# AVR32SD28 device description
Architecture: AVR8X; Family: AVR
Registers are 8-bit, read-write, reset 0x0 unless marked. A register's access mark holds for its fields unless they carry their own. Offsets are from the block's base; [hi:lo] are bit positions; {n}, {i} and the like mark numbered series; 'fields as' and 'values as' point back to an identical list.

## FUSE — Fuses
Instances: FUSE 0x1050
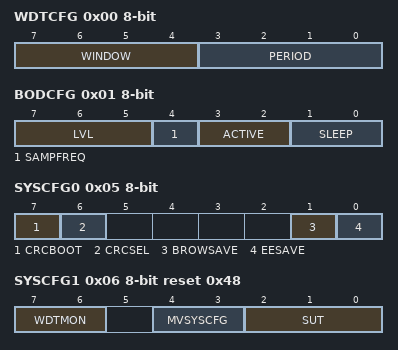
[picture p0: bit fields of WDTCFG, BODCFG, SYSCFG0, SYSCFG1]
0x00 WDTCFG — Watchdog Configuration
  [7:4] WINDOW — Watchdog Window Timeout Period
    0=OFF; 1=8CLK (8 cycles (244 us)); 2=16CLK (16 cycles (488 us)); 3=32CLK (32 cycles (976 us)); 4=64CLK (64 cycles (1.95 ms)); 5=128CLK (128 cycles (3.9 ms)); 6=256CLK (256 cycles (7.8 ms)); 7=512CLK (512 cycles (15.625 ms)); 8=1KCLK (1K cycles (31.25 ms)); 9=2KCLK (2K cycles (62.5 ms)); 10=4KCLK (4K cycles (125 ms)); 11=8KCLK (8K cycles (250 ms))
  [3:0] PERIOD — Watchdog Timeout Period
    values as WINDOW
0x01 BODCFG — BOD Configuration
  [7:5] LVL — BOD Level
    0=BODLEVEL0 (1.9V); 1=BODLEVEL1 (2.45V); 2=BODLEVEL2 (2.7V); 3=BODLEVEL3 (2.85V)
  [4] SAMPFREQ — BOD Sample Frequency
    0=128HZ (Sample frequency is 128 Hz); 1=32HZ (Sample frequency is 32 Hz)
  [3:2] ACTIVE — BOD Operation in Active Mode
    0=DISABLE (BOD disabled); 1=ENABLE (BOD enabled in continuous mode); 2=SAMPLE (BOD enabled in sampled mode); 3=ENABLEWAIT (BOD enabled in continuous mode. Execution is halted at wake-up until BOD is running.)
  [1:0] SLEEP — BOD Operation in Sleep Mode
    0=DISABLE (BOD disabled); 1=ENABLE (BOD enabled in continuous mode); 2=SAMPLE (BOD enabled in sampled mode)
0x05 SYSCFG0 — System Configuration 0
  [7] CRCBOOT
  [6] CRCSEL — CRC Select
    0=CRC16 (Enable CRC16); 1=CRC32 (Enable CRC32)
  [1] BROWSAVE — Boot Row Saved
  [0] EESAVE — EEPROM Save
0x06 SYSCFG1 reset 0x48 — System Configuration 1
  [7:6] WDTMON — WDT Monitor Configuration
    0=OFF (Monitor is disabled); 1=ON (Monitor is always on (Reset value)); 2=SLEEP (Monitor is always on in normal and IDLE mode, but automatically disabled when the MCU is in POWERDOWN and STANDBY sleep modes)
  [4:3] MVSYSCFG — MVIO System Configuration
    1=DUAL (Device used in a dual supply configuration); 2=SINGLE (Device used in a single supply configuration)
  [2:0] SUT — Startup Time
    0=0MS; 1=1MS; 2=2MS; 3=4MS; 4=8MS; 5=16MS; 6=32MS; 7=64MS
0x07 CODESIZE — Code Section Size
0x08 BOOTSIZE — Boot Section Size
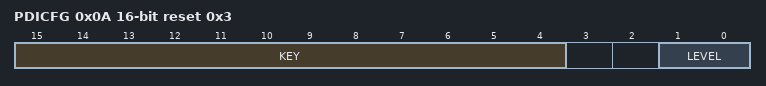
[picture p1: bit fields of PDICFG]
0x0A PDICFG 16-bit reset 0x3 — Programming and Debugging Interface Configuration
  [15:4] KEY — NVM Protection Activation Key select
    0=NOTACT (Not active); 0xB45=NVMACT (NVM Protection active)
  [1:0] LEVEL — Protection Level select
    2=NVMACCDIS (NVM access through UPDI disabled); 3=BASIC (UPDI and UPDI pins working normally)

## GPR — General Purpose Registers
Instances: GPR 0x001C
{0x0+i} GPR{i} reset not defined (i=0..3) — General Purpose Register {i}

## LOCK — Lockbits
Instances: LOCK 0x1040
0x00 KEY 32-bit reset 0x5CC5C55C — Lock Key Bits
  [31:0] KEY — Lock Key
    0=RWLOCK; 0x5CC5C55C=NOLOCK (No locks)

## MVIO — Multi-Voltage I/O
Instances: MVIO 0x0100
0x00 INTCTRL — Interrupt Control
  [0] VDDIO2IE — VDDIO2 Interrupt Enable
0x01 INTFLAGS — Interrupt Flags
  [0] VDDIO2IF — VDDIO2 Interrupt Flag
0x02 STATUS ro
  [0] VDDIO2S — VDDIO2 Status

## NVMCTRL — Non-volatile Memory Controller
Instances: NVMCTRL 0x1000
0x00 CTRLA — Control A
  [6:0] CMD — Command
    0=NOCMD (No Command); 1=NOOP (No Operation); 2=FLWR (Flash Write); 8=FLPER (Flash Page Erase); 9=FLMPER2 (Flash Multi-Page Erase 2 pages); 10=FLMPER4 (Flash Multi-Page Erase 4 pages); 11=FLMPER8 (Flash Multi-Page Erase 8 pages); 12=FLMPER16 (Flash Multi-Page Erase 16 pages); 13=FLMPER32 (Flash Multi-Page Erase 32 pages); 18=EEWR (EEPROM Write); 19=EEERWR (EEPROM Erase and Write); 24=EEBER (EEPROM Byte Erase); 25=EEMBER2 (EEPROM Multi-Byte Erase 2 bytes); 26=EEMBER4 (EEPROM Multi-Byte Erase 4 bytes); 27=EEMBER8 (EEPROM Multi-Byte Erase 8 bytes); 28=EEMBER16 (EEPROM Multi-Byte Erase 16 bytes); 29=EEMBER32 (EEPROM Multi-Byte Erase 32 bytes); 32=CHER (Chip Erase Command); 48=EECHER (EEPROM Erase Command)
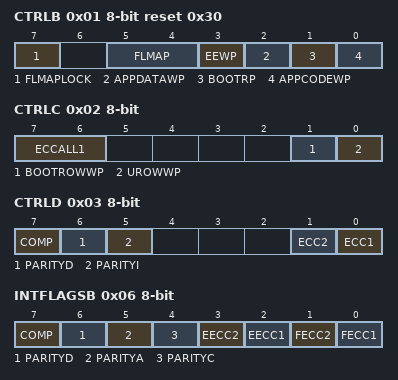
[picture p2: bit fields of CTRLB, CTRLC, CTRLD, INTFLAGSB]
0x01 CTRLB reset 0x30 — Control B
  [7] FLMAPLOCK — Flash Mapping Lock
  [5:4] FLMAP — Flash Mapping in Data space
    {v}=SECTION{v} (Flash section {v}) (v=0..3)
  [3] EEWP — EEPROM Write Protect
  [2] APPDATAWP — Application Data Write Protect
  [1] BOOTRP — Boot Read Protect
  [0] APPCODEWP — Application Code Write Protect
0x02 CTRLC — Control C
  [7:6] ECCALL1 — Erased Flash ECC check
    0=CHECKALL (ECC check on all flash words including those read as all-ones.); 1=DISALL (Disregard ECC check on flash words read as all-ones from the entire flash.); 2=DISAPPDATA (Disregard ECC check on flash words read as all-ones from from the APPDATA section or USER row); 3=DISAPPDATAEE (Disregard ECC check on EEPROM bytes read as all-ones, and flash words read as all-ones from the APPDATA section, USER row, or BOOTROW)
  [1] BOOTROWWP — Boot Row Write Protect
  [0] UROWWP — User Row Write Protect
0x03 CTRLD — Control D
  [7] COMP — ECC comparator error inject
  [6] PARITYD — Parity error inject on Data Read
  [5] PARITYI — Parity error inject on Instruction Fetch
  [1] ECC2 — 2-bit ECC error inject
  [0] ECC1 — 1-bit ECC error inject
0x04 INTCTRLA — Interrupt Control A
  [0] EEREADY — EEPROM Ready
0x05 INTFLAGSA — Interrupt Flags A
  [0] EEREADY — EEPROM Ready
0x06 INTFLAGSB reset not defined — Interrupt Flags B
  [7] COMP — Comparator error detected
  [6] PARITYD — Parity error on Write Data detected
  [5] PARITYA — Parity error on Address detected
  [4] PARITYC — Parity error on Control signals detected
  [3] EECC2 — EEPROM multibit error detected
  [2] EECC1 — EEPROM 1-bit error detected
  [1] FECC2 — Flash multibit error detected
  [0] FECC1 — Flash 1-bit ECC error detected
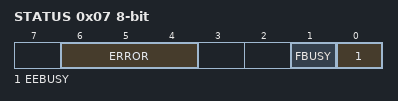
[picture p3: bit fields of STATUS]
0x07 STATUS
  [6:4] ERROR — Write error
    0=NONE (No Error); 1=INVALIDCMD (Write command not selected or not valid); 2=WRITEPROTECT (Write to section not allowed); 3=CMDCOLLISION (Selecting new write command while programming is ongoing)
  [1] FBUSY ro — Flash busy
  [0] EEBUSY ro — EEPROM busy
0x08 DATA 32-bit ro
0x0C ADDR 32-bit reset not defined — Address
  [23:0] ADDR
0x10 PARITY ro reset not defined — ECC Parity
0x11 SYNDROME ro reset not defined — ECC Syndrome
